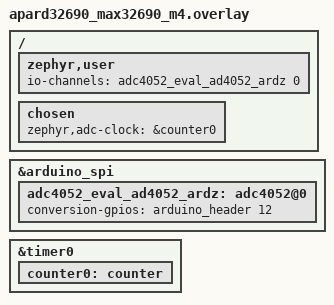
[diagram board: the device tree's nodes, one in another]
/*
 * Copyright (c) 2025 Analog Devices, Inc.
 *
 * SPDX-License-Identifier: Apache-2.0
 */

/ {
	zephyr,user {
		io-channels = <&adc4052_eval_ad4052_ardz 0>;
	};
};

&arduino_spi {
	adc4052_eval_ad4052_ardz: adc4052@0 {
		conversion-gpios = <&arduino_header 12 (GPIO_ACTIVE_HIGH | MAX32_GPIO_VSEL_VDDIOH)>;
	};
};

&timer0 {
	status = "okay";

	counter0: counter {
		status = "okay";
	};
};

/ {
	chosen {
		zephyr,adc-clock = &counter0;
	};
};
